VERSION "v0.0.1"

NS_ :

BS_:

BU_: CVC CAN_simulator

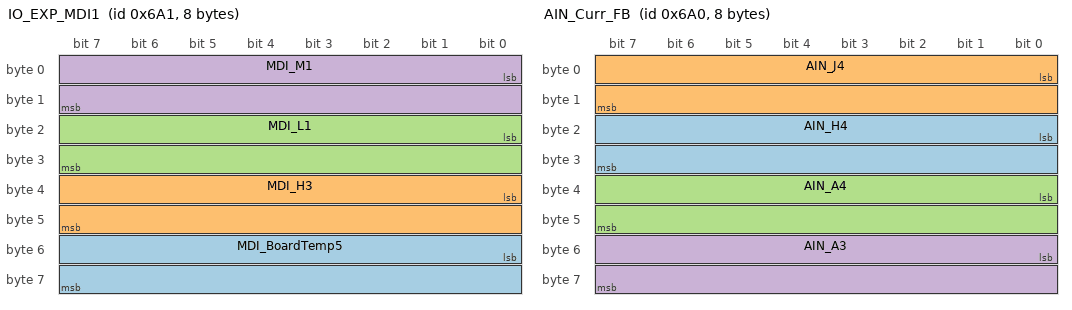
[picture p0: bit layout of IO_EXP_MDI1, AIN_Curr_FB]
BO_ 1697 IO_EXP_MDI1: 8 Vector__XXX
 SG_ MDI_BoardTemp5 : 48|16@1- (0.1,0) [-3276.8|3276.7] "C" Vector__XXX
 SG_ MDI_H3 : 32|16@1+ (1,0) [0|65535] "mV" Vector__XXX
 SG_ MDI_L1 : 16|16@1+ (1,0) [0|65535] "mV" Vector__XXX
 SG_ MDI_M1 : 0|16@1+ (1,0) [0|65535] "mV" Vector__XXX

BO_ 1696 AIN_Curr_FB: 8 Vector__XXX
 SG_ AIN_H4 : 16|16@1+ (1,0) [0|65535] "uA" Vector__XXX
 SG_ AIN_J4 : 0|16@1+ (1,0) [0|65535] "uA" Vector__XXX
 SG_ AIN_A4 : 32|16@1+ (1,0) [0|65535] "uA" Vector__XXX
 SG_ AIN_A3 : 48|16@1+ (1,0) [0|65535] "uA" Vector__XXX

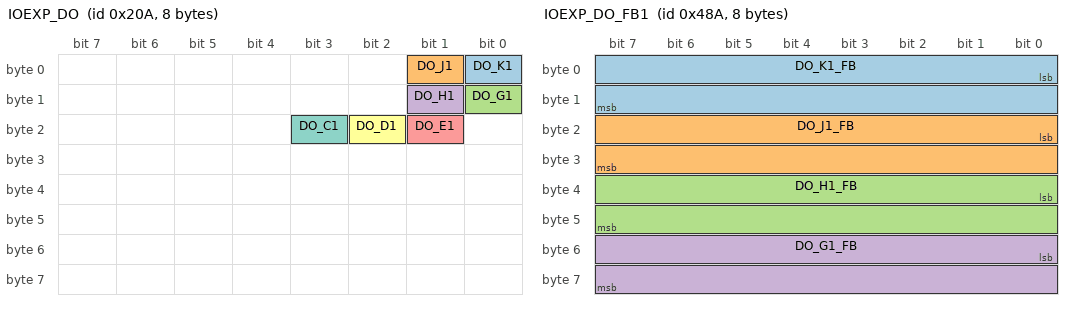
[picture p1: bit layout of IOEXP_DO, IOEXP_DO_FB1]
BO_ 522 IOEXP_DO: 8 Vector__XXX
 SG_ DO_K1 : 0|1@1+ (1,0) [0|1] "" Vector__XXX
 SG_ DO_J1 : 1|1@1+ (1,0) [0|1] "" Vector__XXX
 SG_ DO_G1 : 8|1@1+ (1,0) [0|1] "" Vector__XXX
 SG_ DO_H1 : 9|1@1+ (1,0) [0|1] "" Vector__XXX
 SG_ DO_E1 : 17|1@1+ (1,0) [0|1] "" Vector__XXX
 SG_ DO_D1 : 18|1@1+ (1,0) [0|1] "" Vector__XXX
 SG_ DO_C1 : 19|1@1+ (1,0) [0|1] "" Vector__XXX

BO_ 1162 IOEXP_DO_FB1: 8 Vector__XXX
 SG_ DO_K1_FB : 0|16@1+ (1,0) [0|65535] "mV" Vector__XXX
 SG_ DO_J1_FB : 16|16@1+ (1,0) [0|65535] "mV" Vector__XXX
 SG_ DO_H1_FB : 32|16@1+ (1,0) [0|65535] "mA" Vector__XXX
 SG_ DO_G1_FB : 48|16@1+ (1,0) [0|65535] "mA" Vector__XXX

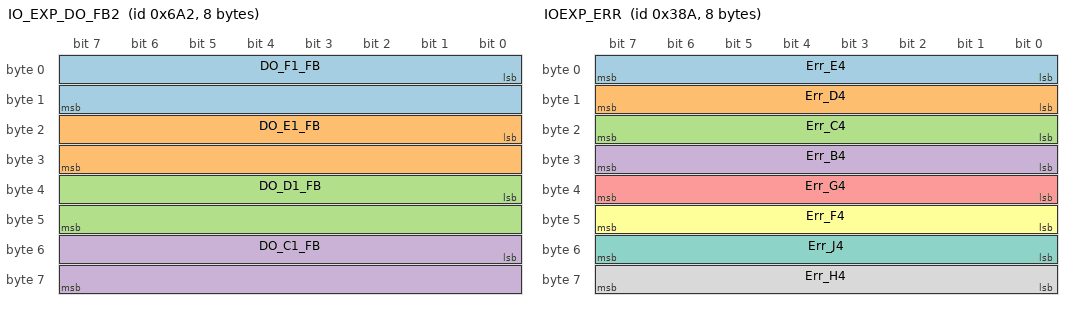
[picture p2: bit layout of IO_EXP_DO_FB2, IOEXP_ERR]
BO_ 1698 IO_EXP_DO_FB2: 8 Vector__XXX
 SG_ DO_F1_FB : 0|16@1+ (1,0) [0|65535] "mA" Vector__XXX
 SG_ DO_E1_FB : 16|16@1+ (1,0) [0|65535] "mA" Vector__XXX
 SG_ DO_D1_FB : 32|16@1+ (1,0) [0|65535] "mA" Vector__XXX
 SG_ DO_C1_FB : 48|16@1+ (1,0) [0|65535] "mA" Vector__XXX

BO_ 906 IOEXP_ERR: 8 Vector__XXX
 SG_ Err_E4 : 0|8@1+ (1,0) [0|255] "" Vector__XXX
 SG_ Err_D4 : 8|8@1+ (1,0) [0|255] "" Vector__XXX
 SG_ Err_C4 : 16|8@1+ (1,0) [0|255] "" Vector__XXX
 SG_ Err_B4 : 24|8@1+ (1,0) [0|255] "" Vector__XXX
 SG_ Err_G4 : 32|8@1+ (1,0) [0|255] "" Vector__XXX
 SG_ Err_F4 : 40|8@1+ (1,0) [0|255] "" Vector__XXX
 SG_ Err_J4 : 48|8@1+ (1,0) [0|255] "" Vector__XXX
 SG_ Err_H4 : 56|8@1+ (1,0) [0|255] "" Vector__XXX

BO_ 650 IOEXP_DI_FB: 8 Vector__XXX
 SG_ DIN_F4 : 1|1@1+ (1,0) [0|1] "" Vector__XXX
 SG_ DIN_G4 : 0|1@1+ (1,0) [0|1] "" Vector__XXX

BO_ 778 IOEXP_PWM: 2 Vector__XXX
 SG_ PWM_F1_DutyCycle : 0|16@1+ (0.00152590218966964,0) [0|100] "%" Vector__XXX

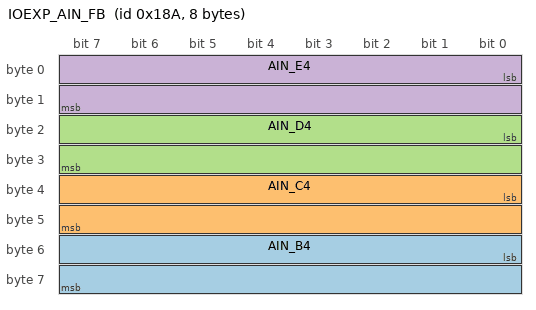
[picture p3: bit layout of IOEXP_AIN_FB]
BO_ 394 IOEXP_AIN_FB: 8 Vector__XXX
 SG_ AIN_B4 : 48|16@1+ (1,0) [0|65535] "mV" Vector__XXX
 SG_ AIN_C4 : 32|16@1+ (1,0) [0|65535] "mV" Vector__XXX
 SG_ AIN_D4 : 16|16@1+ (1,0) [0|65535] "mV" Vector__XXX
 SG_ AIN_E4 : 0|16@1+ (1,0) [0|65535] "mV" Vector__XXX

BA_DEF_  "DBName" STRING ;
BA_DEF_  "BusType" STRING ;
BA_DEF_ BU_  "NmStationAddress" INT 0 255;
BA_DEF_ BO_  "CanDootDecode" ENUM  "No","Yes";
BA_DEF_ BO_  "CanDootSimulateCycleTime" INT 0 50000;
BA_DEF_ SG_  "CanDootHidden" ENUM  "No","Yes";
BA_DEF_ BO_  "VFrameFormat" ENUM  "StandardCAN","ExtendedCAN","reserved","J1939PG","reserved","reserved","reserved","reserved","reserved","reserved","reserved","reserved","reserved","reserved","StandardCAN_FD","ExtendedCAN_FD";
BA_DEF_ BO_  "CanDootDecodeBus" INT 0 6;
BA_DEF_ BO_  "CanDootSimulateBus" INT 0 6;
BA_DEF_ SG_  "CanDootBroadcast" ENUM  "No","Yes";
BA_DEF_ SG_  "CG_VarType" ENUM  "bool","uint8_t","int8_t","uint16_t","int16_t","uint32_t","int32_t","float","double";
BA_DEF_DEF_  "DBName" "";
BA_DEF_DEF_  "BusType" "CAN";
BA_DEF_DEF_  "NmStationAddress" 254;
BA_DEF_DEF_  "CanDootDecode" "Yes";
BA_DEF_DEF_  "CanDootSimulateCycleTime" 1500;
BA_DEF_DEF_  "CanDootHidden" "Yes";
BA_DEF_DEF_  "VFrameFormat" "StandardCAN";
BA_DEF_DEF_  "CanDootDecodeBus" 1;
BA_DEF_DEF_  "CanDootSimulateBus" 1;
BA_DEF_DEF_  "CanDootBroadcast" "Yes";
BA_DEF_DEF_  "CG_VarType" "uint8_t";
BA_ "BusType" "CAN FD";
BA_ "DBName" "candoot_Tester";
